# cyt6bj register map
Vendor: Cypress Semiconductor; Series: cyt6bj; File version: 1.0
CPU: CM7 r0p1, little endian, MPU, FPU, VTOR, 3 interrupt priority bits
Registers are 32-bit, read-write, reset 0x0 unless marked. A register's access mark holds for its fields unless they carry their own. Offsets are from the block's base; [hi:lo] are bit positions; lines under a group give offsets from that group; {n}, {i} and the like mark numbered series; <NAME> marks a mode.

## CANFD0 (part 2 of 3) — CAN Controller
Base 0x40520000
Same registers: CANFD1 0x40540000
{0x0+0x200*i} CH[{i}] (i=0..4) group — FIFO wrapper around M_TTCAN 3PIP, to enable DMA
  0x00 M_TTCAN group — TTCAN 3PIP, includes FD
    0xAC RXBC — Rx Buffer Configuration
      [15:2] RBSA — Rx Buffer Start Address Configures the start address of the Rx Buffers section in the Message RAM (32-bit word address). Also used to reference debug messages A,B,C.
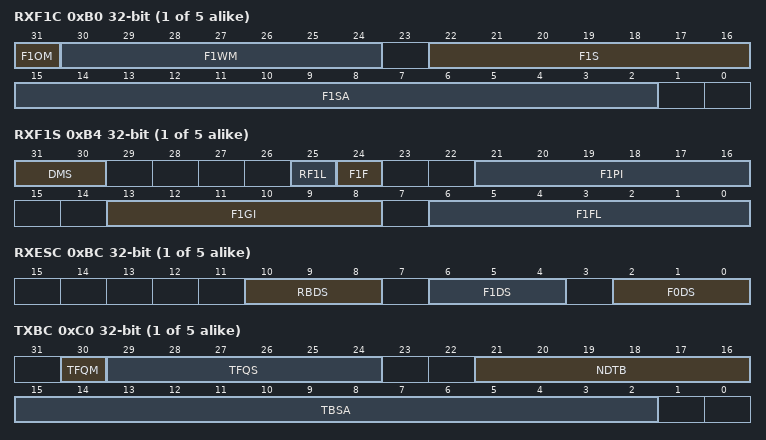
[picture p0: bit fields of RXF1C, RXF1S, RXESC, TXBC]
    0xB0 RXF1C — Rx FIFO 1 Configuration
      [31] F1OM — FIFO 1 Operation Mode FIFO 1 can be operated in blocking or in overwrite mode (see Section 3.4.2). 0= FIFO 1 blocking mode 1= FIFO 1 overwrite mode
      [30:24] F1WM — Rx FIFO 1 Watermark 0= Watermark interrupt disabled 1-64= Level for Rx FIFO 1 watermark interrupt (IR.RF1W) 64= Watermark interrupt disabled
      [22:16] F1S — Rx FIFO 1 Size 0= No Rx FIFO 1 1-64= Number of Rx FIFO 1 elements 64= Values greater than 64 are interpreted as 64 The Rx FIFO 1 elements are indexed from 0 to F1S - 1
      [15:2] F1SA — Rx FIFO 1 Start Address Start address of Rx FIFO 1 in Message RAM (32-bit word address, see Figure 2).
    0xB4 RXF1S ro — Rx FIFO 1 Status
      [31:30] DMS — Debug Message Status 00= Idle state, wait for reception of debug messages, DMA request is cleared 01= Debug message A received 10= Debug messages A, B received 11= Debug messages A, B, C received, DMA request is set
      [25] RF1L — Rx FIFO 1 Message Lost This bit is a copy of interrupt flag IR.RF1L. When IR.RF1L is reset, this bit is also reset. 0= No Rx FIFO 1 message lost 1= Rx FIFO 1 message lost, also set after write attempt to Rx FIFO 1 of size zero
      [24] F1F — Rx FIFO 1 Full 0= Rx FIFO 1 not full 1= Rx FIFO 1 full
      [21:16] F1PI — Rx FIFO 1 Put Index Rx FIFO 1 write index pointer, range 0 to 63.
      [13:8] F1GI — Rx FIFO 1 Get Index Rx FIFO 1 read index pointer, range 0 to 63. This field is updated by the software writing to RXF1A.F1AI. When the software reading the value immediately after writing to RXF1A.F1AI, this value should be read twice to ensure that the update is reflected.
      [6:0] F1FL — Rx FIFO 1 Fill Level Number of elements stored in Rx FIFO 1, range 0 to 64. When the software reading the value immediately after writing to RXF1A.F1AI, this value should be read twice to ensure that the update is reflected.
    0xB8 RXF1A — Rx FIFO 1 Acknowledge
      [5:0] F1AI — Rx FIFO 1 Acknowledge Index After the Host has read a message or a sequence of messages from Rx FIFO 1 it has to write the buffer index of the last element read from Rx FIFO 1 to F1AI. This will set the Rx FIFO 1 Get Index RXF1S.F1GI to F1AI + 1 and update the FIFO 1 Fill Level RXF1S.F1FL.
    0xBC RXESC — Rx Buffer / FIFO Element Size Configuration
      [10:8] RBDS — Rx Buffer Data Field Size 000= 8 byte data field 001= 12 byte data field 010= 16 byte data field 011= 20 byte data field 100= 24 byte data field 101= 32 byte data field 110= 48 byte data field 111= 64 byte data field
      [6:4] F1DS — Rx FIFO 1 Data Field Size 000= 8 byte data field 001= 12 byte data field 010= 16 byte data field 011= 20 byte data field 100= 24 byte data field 101= 32 byte data field 110= 48 byte data field 111= 64 byte data field
      [2:0] F0DS — Rx FIFO 0 Data Field Size 000= 8 byte data field 001= 12 byte data field 010= 16 byte data field 011= 20 byte data field 100= 24 byte data field 101= 32 byte data field 110= 48 byte data field 111= 64 byte data field
    0xC0 TXBC — Tx Buffer Configuration
      [30] TFQM — Tx FIFO/Queue Mode 0= Tx FIFO operation 1= Tx Queue operation
      [29:24] TFQS — Transmit FIFO/Queue Size 0= No Tx FIFO/Queue 1-32= Number of Tx Buffers used for Tx FIFO/Queue 32= Values greater than 32 are interpreted as 32
      [21:16] NDTB — Number of Dedicated Transmit Buffers 0= No Dedicated Tx Buffers 1-32= Number of Dedicated Tx Buffers 32= Values greater than 32 are interpreted as 32
      [15:2] TBSA — Tx Buffers Start Address Start address of Tx Buffers section in Message RAM (32-bit word address, see Figure 2).
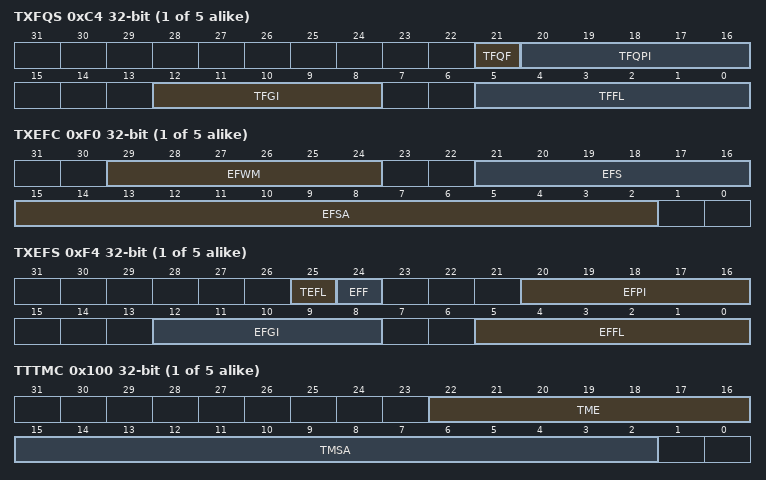
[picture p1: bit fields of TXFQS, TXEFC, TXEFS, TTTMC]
    0xC4 TXFQS ro — Tx FIFO/Queue Status
      [21] TFQF — Tx FIFO/Queue Full 0= Tx FIFO/Queue not full 1= Tx FIFO/Queue full
      [20:16] TFQPI — Tx FIFO/Queue Put Index Tx FIFO/Queue write index pointer, range 0 to 31.
      [12:8] TFGI — Tx FIFO Get Index Tx FIFO read index pointer, range 0 to 31. Read as zero when Tx Queue operation is configured TXBC.TFQM = '1').
      [5:0] TFFL — Tx FIFO Free Level Number of consecutive free Tx FIFO elements starting from TFGI, range 0 to 32. Read as zero when Tx Queue operation is configured (TXBC.TFQM = '1')
    0xC8 TXESC — Tx Buffer Element Size Configuration
      [2:0] TBDS — Tx Buffer Data Field Size 000= 8 byte data field 001= 12 byte data field 010= 16 byte data field 011= 20 byte data field 100= 24 byte data field 101= 32 byte data field 110= 48 byte data field 111= 64 byte data field
    0xCC TXBRP ro — Tx Buffer Request Pending
      [31:0] TRP — Transmission Request Pending Each Tx Buffer has its own Transmission Request Pending bit. The bits are set via register TXBAR. The bits are reset after a requested transmission has completed or has been cancelled via register TXBCR. TXBRP bits are set only for those Tx Buffers configured via TXBC. After a TXBRP bit has been set, a Tx scan (see Section 3.5, Tx Handling) is started to check for the pending Tx request with the highest priority (Tx Buffer with lowest Message ID). A cancellation request resets the corresponding transmission request pending bit of register TXBRP. In case a transmission has already been started when a cancellation is requested, this is done at the end of the transmission, regardless whether the transmission was successful or not. The cancellation request bits are reset directly after the corresponding TXBRP bit has been reset. After a cancellation has been requested, a finished cancellation is signaled via TXBCF after successful transmission together with the corresponding TXBTO bit when the transmission has not yet been started at the point of cancellation when the transmission has been aborted due to lost arbitration when an error occurred during frame transmission In DAR mode all transmissions are automatically cancelled if they are not successful. The corresponding TXBCF bit is set for all unsuccessful transmissions. 0= No transmission request pending 1= Transmission request pending
    0xD0 TXBAR — Tx Buffer Add Request
      [31:0] AR — Add Request Each Tx Buffer has its own Add Request bit. Writing a '1' will set the corresponding Add Request bit; writing a '0' has no impact. This enables the Host to set transmission requests for multiple Tx Buffers with one write to TXBAR. TXBAR bits are set only for those Tx Buffers configured via TXBC. When no Tx scan is running, the bits are reset immediately, else the bits remain set until the Tx scan process has completed. 0= No transmission request added 1= Transmission requested added
    0xD4 TXBCR — Tx Buffer Cancellation Request
      [31:0] CR — Cancellation Request Each Tx Buffer has its own Cancellation Request bit. Writing a '1' will set the corresponding Cancellation Request bit; writing a '0' has no impact. This enables the Host to set cancellation requests for multiple Tx Buffers with one write to TXBCR. TXBCR bits are set only for those Tx Buffers configured via TXBC. The bits remain set until the corresponding bit of TXBRP is reset. 0= No cancellation pending 1= Cancellation pending
    0xD8 TXBTO ro — Tx Buffer Transmission Occurred
      [31:0] TO — Transmission Occurred Each Tx Buffer has its own Transmission Occurred bit. The bits are set when the corresponding TXBRP bit is cleared after a successful transmission. The bits are reset when a new transmission is requested by writing a '1' to the corresponding bit of register TXBAR. 0= No transmission occurred 1= Transmission occurred
    0xDC TXBCF ro — Tx Buffer Cancellation Finished
      [31:0] CF — Cancellation Finished Each Tx Buffer has its own Cancellation Finished bit. The bits are set when the corresponding TXBRP bit is cleared after a cancellation was requested via TXBCR. In case the corresponding TXBRP bit was not set at the point of cancellation, CF is set immediately. The bits are reset when a new transmission is requested by writing a '1' to the corresponding bit of register TXBAR. 0= No transmit buffer cancellation 1= Transmit buffer cancellation finished
    0xE0 TXBTIE — Tx Buffer Transmission Interrupt Enable
      [31:0] TIE — Transmission Interrupt Enable Each Tx Buffer has its own Transmission Interrupt Enable bit. 0= Transmission interrupt disabled 1= Transmission interrupt enable
    0xE4 TXBCIE — Tx Buffer Cancellation Finished Interrupt Enable
      [31:0] CFIE — Cancellation Finished Interrupt Enable Each Tx Buffer has its own Cancellation Finished Interrupt Enable bit. 0= Cancellation finished interrupt disabled 1= Cancellation finished interrupt enabled
    0xF0 TXEFC — Tx Event FIFO Configuration
      [29:24] EFWM — Event FIFO Watermark 0= Watermark interrupt disabled 1-32= Level for Tx Event FIFO watermark interrupt (IR.TEFW) 32= Watermark interrupt disabled
      [21:16] EFS — Event FIFO Size 0= Tx Event FIFO disabled 1-32= Number of Tx Event FIFO elements 32= Values greater than 32 are interpreted as 32 The Tx Event FIFO elements are indexed from 0 to EFS-1
      [15:2] EFSA — Event FIFO Start Address Start address of Tx Event FIFO in Message RAM (32-bit word address, see Figure 2).
    0xF4 TXEFS ro — Tx Event FIFO Status
      [25] TEFL — Tx Event FIFO Element Lost This bit is a copy of interrupt flag IR.TEFL. When IR.TEFL is reset, this bit is also reset. 0= No Tx Event FIFO element lost 1= Tx Event FIFO element lost, also set after write attempt to Tx Event FIFO of size zero.
      [24] EFF — Event FIFO Full 0= Tx Event FIFO not full 1= Tx Event FIFO full
      [20:16] EFPI — Event FIFO Put Index Tx Event FIFO write index pointer, range 0 to 31.
      [12:8] EFGI — Event FIFO Get Index Tx Event FIFO read index pointer, range 0 to 31. This field is updated by the software writing to TXEFA.EFAI. When the software reading the value immediately after writing to TXEFA.EFAI, this value should be read twice to ensure that the update is reflected.
      [5:0] EFFL — Event FIFO Fill Level Number of elements stored in Tx Event FIFO, range 0 to 32. When the software reading the value immediately after writing to TXEFA.EFAI, this value should be read twice to ensure that the update is reflected.
    0xF8 TXEFA — Tx Event FIFO Acknowledge
      [4:0] EFAI — Event FIFO Acknowledge Index After the Host has read an element or a sequence of elements from the Tx Event FIFO it has to write the index of the last element read from Tx Event FIFO to EFAI. This will set the Tx Event FIFO Get Index TXEFS.EFGI to EFAI + 1 and update the Event FIFO Fill Level TXEFS.EFFL.
    0x100 TTTMC — TT Trigger Memory Configuration
      [22:16] TME — Trigger Memory Elements 0= No Trigger Memory 1-64= Number of Trigger Memory elements 64= Values greater than 64 are interpreted as 64
      [15:2] TMSA — Trigger Memory Start Address Start address of Trigger Memory in Message RAM (32-bit word address, see Figure 2).
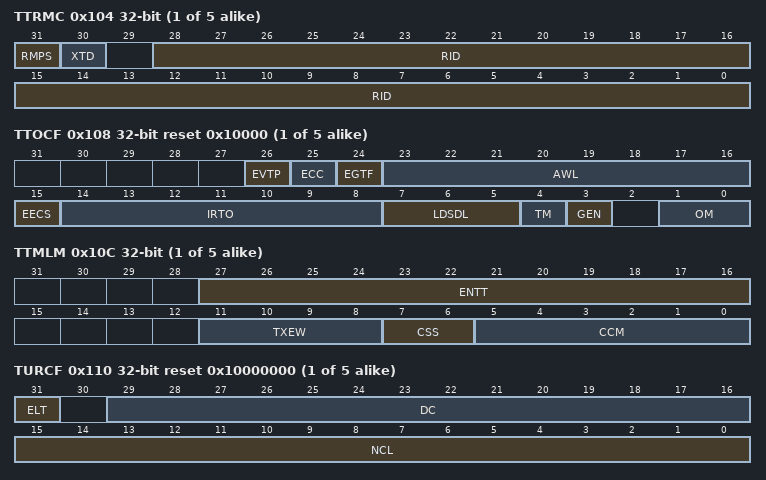
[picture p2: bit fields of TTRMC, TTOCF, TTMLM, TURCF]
    0x104 TTRMC — TT Reference Message Configuration
      [31] RMPS — Reference Message Payload Select Ignored in case of time slaves. 0= Reference message has no additional payload 1= The following elements are taken from Tx Buffer 0: Message Marker MM, Event FIFO Control EFC, Data Length Code DLC, Data Bytes DB Level 1: bytes 2-8, Level 0,2: bytes 5-8)
      [30] XTD — Extended Identifier 0= 11-bit standard identifier 1= 29-bit extended identifier
      [28:0] RID — Reference Identifier Identifier transmitted with reference message and used for reference message filtering. Standard or extended reference identifier depending on bit XTD. A standard identifier has to be written to ID[28:18].
    0x108 TTOCF reset 0x10000 — TT Operation Configuration
      [26] EVTP — Event Trigger Polarity 0= Rising edge trigger 1= Falling edge trigger
      [25] ECC — Enable Clock Calibration 0= Automatic clock calibration in TTCAN Level 0,2 is disabled 1= Automatic clock calibration in TTCAN Level 0,2 is enabled
      [24] EGTF — Enable Global Time Filtering 0= Global time filtering in TTCAN Level 0,2 is disabled 1= Global time filtering in TTCAN Level 0,2 is enabled
      [23:16] AWL — Application Watchdog Limit The application watchdog can be disabled by programming AWL to 0x00. 0x00-FF Maximum time after which the application has to serve the application watchdog. The application watchdog is incremented once each 256 NTUs.
      [15] EECS — Enable External Clock Synchronization If enabled, TUR configuration (TURCF.NCL only) may be updated during TTCAN operation. 0= External clock synchronization in TTCAN Level 0,2 disabled 1= External clock synchronization in TTCAN Level 0,2 enabled
      [14:8] IRTO — Initial Reference Trigger Offset 0x00-7F Positive offset, range from 0 to 127
      [7:5] LDSDL — LD of Synchronization Deviation Limit The Synchronization Deviation Limit SDL is configured by its dual logarithm LDSDL with SDL = 2(LDSDL + 5). It should not exceed the clock tolerance given by the CAN bit timing configuration. 0x0-7 LD of Synchronization Deviation Limit (SDL <= 32...4096)
      [4] TM — Time Master 0= Time Master function disabled 1= Potential Time Master
      [3] GEN — Gap Enable 0= Strictly time-triggered operation 1= External event-synchronized time-triggered operation
      [1:0] OM — Operation Mode 00= Event-driven CAN communication, default 01= TTCAN level 1 10= TTCAN level 2 11= TTCAN level 0
    0x10C TTMLM — TT Matrix Limits
      [27:16] ENTT — Expected Number of Tx Triggers 0x000-FFF Expected number of Tx Triggers in one Matrix Cycle
      [11:8] TXEW — Tx Enable Window 0x0-F Length of Tx enable window, 1-16 NTU cycles
      [7:6] CSS
      [5:0] CCM
    0x110 TURCF reset 0x10000000 — TUR Configuration
      [31] ELT — Enable Local Time 0= Local time is stopped, default 1= Local time is enabled
      [29:16] DC — Denominator Configuration 0x0000 Illegal value 0x0001-3FFF Denominator Configuration
      [15:0] NCL — Numerator Configuration Low Write access to the TUR Numerator Configuration Low is only possible during configuration with TURCF.ELT = '0' or if TTOCF.EECS (external clock synchronization enabled) is set. When a new value for NCL is written outside TT Configuration Mode, the new value takes effect when TTOST.WECS is cleared to '0'. NCL is locked TTOST.WECS is '1'. 0x0000-FFFF Numerator Configuration Low
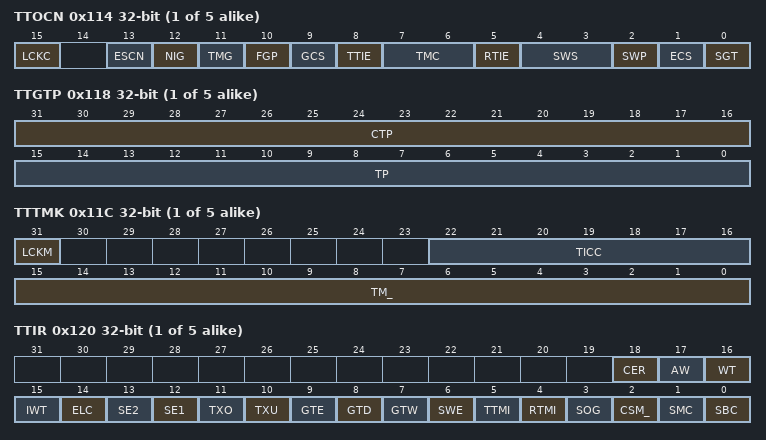
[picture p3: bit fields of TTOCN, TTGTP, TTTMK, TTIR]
    0x114 TTOCN — TT Operation Control
      [15] LCKC ro — TT Operation Control Register Locked Set by a write access to register TTOCN. Reset when the updated configuration has been synchronized into the CAN clock domain. 0= Write access to TTOCN enabled 1= Write access to TTOCN locked
      [13] ESCN — External Synchronization Control If enabled the M_TTCAN synchronizes its cycle time phase to an external event signaled by a rising edge at pin m_ttcan_evt (see Section 4.11). 0= External synchronization disabled 1= External synchronization enabled
      [12] NIG — Next is Gap This bit can only be set when the M_TTCAN is the actual Time Master and when it is configured for external event-synchronized time-triggered operation (TTOCF.GEN = '1') 0= No action, reset by reception of any reference message 1= Transmit next reference message with Next_is_Gap = '1'
      [11] TMG — Time Mark Gap 0= Reset by each reference message 1= Next reference message started when Register Time Mark interrupt TTIR.RTMI is activated
      [10] FGP — Finish Gap Set by the CPU, reset by each reference message 0= No reference message requested 1= Application requested start of reference message
      [9] GCS — Gap Control Select 0= Gap control independent from m_ttcan_evt 1= Gap control by input pin m_ttcan_evt
      [8] TTIE — Trigger Time Mark Interrupt Pulse Enable External time mark events are configured by trigger memory element TMEX (see Section 2.4.7). A trigger time mark interrupt pulse is generated when the trigger memory element becomes active, and the M_TTCAN is in synchronization state In_Schedule or In_Gap. 0= Trigger Time Mark Interrupt output m_ttcan_tmp disabled 1= Trigger Time Mark Interrupt output m_ttcan_tmp enabled
      [7:6] TMC — Register Time Mark Compare 00= No Register Time Mark Interrupt generated 01= Register Time Mark Interrupt if Time Mark = cycle time 10= Register Time Mark Interrupt if Time Mark = local time 11= Register Time Mark Interrupt if Time Mark = global time
      [5] RTIE — Register Time Mark Interrupt Pulse Enable Register time mark interrupts are configured by register TTTMK. A register time mark interrupt pulse with the length of one NTU is generated when the time referenced by TTOCN.TMC (cycle, local, or global) equals TTTMK.TM, independent of the synchronization state. 0= Register Time Mark Interrupt output m_ttcan_rtp disabled 1= Register Time Mark Interrupt output m_ttcan_rtp enabled
      [4:3] SWS — Stop Watch Source 00= Stop Watch disabled 01= Actual value of cycle time is copied to TTCPT.SWV 10= Actual value of local time is copied to TTCPT.SWV 11= Actual value of global time is copied to TTCPT.SWV
      [2] SWP — Stop Watch Polarity 0= Rising edge trigger 1= Falling edge trigger
      [1] ECS — External Clock Synchronization Writing a '1' to ECS sets TTOST.WECS if the node is the actual Time Master. ECS is reset after one Host clock period. The external clock synchronization takes effect at the start of the next basic cycle.
      [0] SGT — Set Global time Writing a '1' to SGT sets TTOST.WGDT if the node is the actual Time Master. SGT is reset after one Host clock period. The global time preset takes effect when the node transmits the next reference message with the Master_Ref_Mark modified by the preset value written to TTGTP.
    0x118 TTGTP — TT Global Time Preset
      [31:16] CTP — Cycle Time Target Phase CTP is write-protected while TTOCN.ESCN or TTOST.SPL are set (see Section 4.11). 0x0000-FFFF Defines target value of cycle time when a rising edge of m_ttcan_evt is expected
      [15:0] TP
    0x11C TTTMK — TT Time Mark
      [31] LCKM ro — TT Time Mark Register Locked Always set by a write access to registers TTOCN. Set by write access to register TTTMK when TTOCN.TMC != '00'. Reset when the registers have been synchronized into the CAN clock domain. 0= Write access to TTTMK enabled 1= Write access to TTTMK locked
      [22:16] TICC — Time Mark Cycle Code Cycle count for which the time mark is valid. 0b000000x valid for all cycles 0b000001c valid every second cycle at cycle count mod2 = c 0b00001cc valid every fourth cycle at cycle count mod4 = cc 0b0001ccc valid every eighth cycle at cycle count mod8 = ccc 0b001cccc valid every sixteenth cycle at cycle count mod16 = cccc 0b01ccccc valid every thirty-second cycle at cycle count mod32 = ccccc 0b1cccccc valid every sixty-fourth cycle at cycle count mod64 = cccccc
      [15:0] TM_ — Time Mark 0x0000-FFFF Time Mark
    0x120 TTIR — TT Interrupt Register
      [18] CER — Configuration Error Trigger out of order. 0= No error found in trigger list 1= Error found in trigger list
      [17] AW — Application Watchdog 0= Application watchdog served in time 1= Application watchdog not served in time
      [16] WT — Watch Trigger 0= No missing reference message 1= Missing reference message (Level 0: cycle time 0xFF00)
      [15] IWT — Initialization Watch Trigger The initialization is restarted by resetting IWT. 0= No missing reference message during system startup 1= No system startup due to missing reference message
      [14] ELC — Error Level Changed Not set when error level changed during initialization. 0= No change in error level 1= Error level changed
      [13] SE2 — Scheduling Error 2 0= No scheduling error 2 1= Scheduling error 2 occurred
      [12] SE1 — Scheduling Error 1 0= No scheduling error 1 1= Scheduling error 1 occurred
      [11] TXO — Tx Count Overflow 0= Number of Tx Trigger as expected 1= More Tx trigger than expected in one matrix cycle
      [10] TXU — Tx Count Underflow 0= Number of Tx Trigger as expected 1= Less Tx trigger than expected in one matrix cycle
      [9] GTE — Global Time Error Synchronization deviation SD exceeds limit specified by TTOCF.LDSDL, TTCAN Level 0,2 only. 0= Synchronization deviation within limit 1= Synchronization deviation exceeded limit
      [8] GTD — Global Time Discontinuity 0= No discontinuity of global time 1= Discontinuity of global time
      [7] GTW — Global Time Wrap 0= No global time wrap occurred 1= Global time wrap from 0xFFFF to 0x0000 occurred
      [6] SWE — Stop Watch Event 0= No rising/falling edge at stop watch trigger pin m_ttcan_swt detected 1= Rising/falling edge at stop watch trigger pin m_ttcan_swt detected
      [5] TTMI — Trigger Time Mark Event Internal Internal time mark events are configured by trigger memory element TMIN (see Section 2.4.7). Set when the trigger memory element becomes active, and the M_TTCAN is in synchronization state In_Gap or In_Schedule. 0= Time mark not reached 1= Time mark reached (Level 0: cycle time TTOCF.IRTO * 0x200)
      [4] RTMI — Register Time Mark Interrupt Set when time referenced by TTOCN.TMC (cycle, local, or global) equals TTTMK.TM, independent of the synchronization state. 0= Time mark not reached 1= Time mark reached
      [3] SOG — Start of Gap 0= No reference message seen with Next_is_Gap bit set 1= Reference message with Next_is_Gap bit set becomes valid
      [2] CSM_ — Change of Synchronization Mode 0= No change in master to slave relation or schedule synchronization 1= Master to slave relation or schedule synchronization changed, also set when TTOST.SPL is reset
      [1] SMC — Start of Matrix Cycle 0= No Matrix Cycle started since bit has been reset 1= Matrix Cycle started
      [0] SBC — Start of Basic Cycle 0= No Basic Cycle started since bit has been reset 1= Basic Cycle started
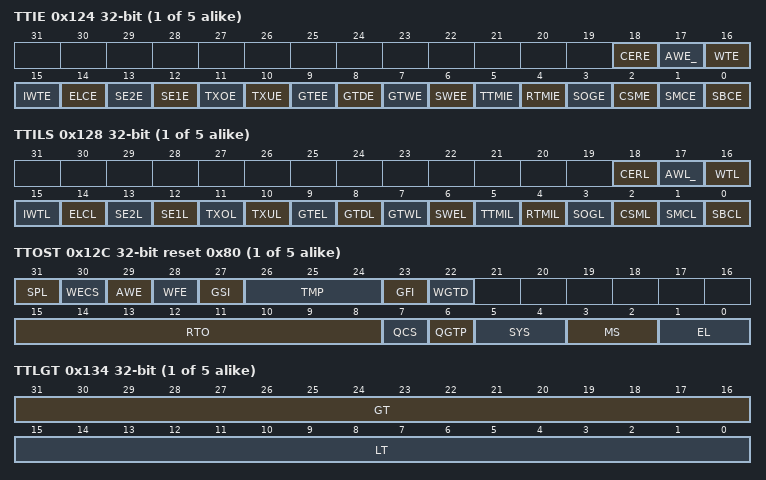
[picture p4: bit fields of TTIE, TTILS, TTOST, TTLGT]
    0x124 TTIE — TT Interrupt Enable
      [18] CERE — Configuration Error Interrupt Enable 0= Interrupt Disabled 1= Interrupt Enabled
      [17] AWE_ — Application Watchdog Interrupt Enable 0= Interrupt Disabled 1= Interrupt Enabled
      [16] WTE — Watch Trigger Interrupt Enable 0= Interrupt Disabled 1= Interrupt Enabled
      [15] IWTE — Initialization Watch Trigger Interrupt Enable 0= Interrupt Disabled 1= Interrupt Enabled
      [14] ELCE — Change Error Level Interrupt Enable 0= Interrupt Disabled 1= Interrupt Enabled
      [13] SE2E — Scheduling Error 2 Interrupt Enable 0= Interrupt Disabled 1= Interrupt Enabled
      [12] SE1E — Scheduling Error 1 Interrupt Enable 0= Interrupt Disabled 1= Interrupt Enabled
      [11] TXOE — Tx Count Overflow Interrupt Enable 0= Interrupt Disabled 1= Interrupt Enabled
      [10] TXUE — Tx Count Underflow Interrupt Enable 0= Interrupt Disabled 1= Interrupt Enabled
      [9] GTEE — Global Time Error Interrupt Enable 0= Interrupt Disabled 1= Interrupt Enabled
      [8] GTDE — Global Time Discontinuity Interrupt Enable 0= Interrupt Disabled 1= Interrupt Enabled
      [7] GTWE — Global Time Wrap Interrupt Enable 0= Interrupt Disabled 1= Interrupt Enabled
      [6] SWEE — Stop Watch Event Interrupt Enable 0= Interrupt Disabled 1= Interrupt Enabled
      [5] TTMIE — Trigger Time Mark Event Internal Enable 0= Interrupt Disabled 1= Interrupt Enabled
      [4] RTMIE — Register Time Mark Interrupt Enable 0= Interrupt Disabled 1= Interrupt Enabled
      [3] SOGE — Start of Gap Interrupt Enable 0= Interrupt Disabled 1= Interrupt Enabled
      [2] CSME — Change of Synchronization Mode Interrupt Enable 0= Interrupt Disabled 1= Interrupt Enabled
      [1] SMCE — Start of Matrix Cycle Interrupt Enable 0= Interrupt Disabled 1= Interrupt Enabled
      [0] SBCE — Start of Basic Cycle Interrupt Enable 0= Interrupt Disabled 1= Interrupt Enabled
    0x128 TTILS — TT Interrupt Line Select
      [18] CERL — Configuration Error Interrupt Select 0= Assign to interrupt enabled by ILE.EINT0 1= Assign to interrupt enabled by ILE.EINT1
      [17] AWL_ — Application Watchdog Interrupt Select 0= Assign to interrupt enabled by ILE.EINT0 1= Assign to interrupt enabled by ILE.EINT1
      [16] WTL — Watch Trigger Interrupt Select 0= Assign to interrupt enabled by ILE.EINT0 1= Assign to interrupt enabled by ILE.EINT1
      [15] IWTL — Initialization Watch Trigger Interrupt Select 0= Assign to interrupt enabled by ILE.EINT0 1= Assign to interrupt enabled by ILE.EINT1
      [14] ELCL — Change Error Level Interrupt Select 0= Assign to interrupt enabled by ILE.EINT0 1= Assign to interrupt enabled by ILE.EINT1
      [13] SE2L — Scheduling Error 2 Interrupt Select 0= Assign to interrupt enabled by ILE.EINT0 1= Assign to interrupt enabled by ILE.EINT1
      [12] SE1L — Scheduling Error 1 Interrupt Select 0= Assign to interrupt enabled by ILE.EINT0 1= Assign to interrupt enabled by ILE.EINT1
      [11] TXOL — Tx Count Overflow Interrupt Select 0= Assign to interrupt enabled by ILE.EINT0 1= Assign to interrupt enabled by ILE.EINT1
      [10] TXUL — Tx Count Underflow Interrupt Select 0= Assign to interrupt enabled by ILE.EINT0 1= Assign to interrupt enabled by ILE.EINT1
      [9] GTEL — Global Time Error Interrupt Select 0= Assign to interrupt enabled by ILE.EINT0 1= Assign to interrupt enabled by ILE.EINT1
      [8] GTDL — Global Time Discontinuity Interrupt Select 0= Assign to interrupt enabled by ILE.EINT0 1= Assign to interrupt enabled by ILE.EINT1
      [7] GTWL — Global Time Wrap Interrupt Select 0= Assign to interrupt enabled by ILE.EINT0 1= Assign to interrupt enabled by ILE.EINT1
      [6] SWEL — Stop Watch Event Interrupt Select 0= Assign to interrupt enabled by ILE.EINT0 1= Assign to interrupt enabled by ILE.EINT1
      [5] TTMIL — Trigger Time Mark Event Internal Select 0= Assign to interrupt enabled by ILE.EINT0 1= Assign to interrupt enabled by ILE.EINT1
      [4] RTMIL — Register Time Mark Interrupt Select 0= Assign to interrupt enabled by ILE.EINT0 1= Assign to interrupt enabled by ILE.EINT1
      [3] SOGL — Start of Gap Interrupt Select 0= Assign to interrupt enabled by ILE.EINT0 1= Assign to interrupt enabled by ILE.EINT1
      [2] CSML — Change of Synchronization Mode Interrupt Select 0= Assign to interrupt enabled by ILE.EINT0 1= Assign to interrupt enabled by ILE.EINT1
      [1] SMCL — Start of Matrix Cycle Interrupt Select 0= Assign to interrupt enabled by ILE.EINT0 1= Assign to interrupt enabled by ILE.EINT1
      [0] SBCL — Start of Basic Cycle Interrupt Select 0= Assign to interrupt enabled by ILE.EINT0 1= Assign to interrupt enabled by ILE.EINT1
    0x12C TTOST ro reset 0x80 — TT Operation Status
      [31] SPL — Schedule Phase Lock The bit is valid only when external synchronization is enabled (TTOCN.ESCN = '1'). In this case it signals that the difference between cycle time configured by TTGTP.CTP and the cycle time at the rising edge at pin m_ttcan_evt is less or equal 9 NTU (see Section 4.11). 0= Phase outside range 1= Phase inside range
      [30] WECS — Wait for External Clock Synchronization 0= No external clock synchronization pending 1= Node waits for external clock synchronization to take effect. The bit is reset at the start of the next basic cycle.
      [29] AWE — Application Watchdog Event The application watchdog is served by reading TTOST. When the watchdog is not served in time, bit AWE is set, all TTCAN communication is stopped, and the M_TTCAN is set into Bus Monitoring Mode. 0= Application Watchdog served in time 1= Failed to serve Application Watchdog in time
      [28] WFE — Wait for Event 0= No Gap announced, reset by a reference message with Next_is_Gap = '0' 1= Reference message with Next_is_Gap = '1' received
      [27] GSI — Gap Started Indicator 0= No Gap in schedule, reset by each reference message and for all time slaves 1= Gap time after Basic Cycle has started
      [26:24] TMP — Time Master Priority 0x0-7 Priority of actual Time Master
      [23] GFI — Gap Finished Indicator Set when the CPU writes TTOCN.FGP, or by a time mark interrupt if TMG = '1', or via input pin m_ttcan_evt if TTOCN.GCS = '1'. Not set by Ref_Trigger_Gap or when Gap is finished by another node sending a reference message. 0= Reset at the end of each reference message 1= Gap finished by M_TTCAN
      [22] WGTD — Wait for Global Time Discontinuity 0= No global time preset pending 1= Node waits for the global time preset to take effect. The bit is reset when the node has transmitted a reference message with Disc_Bit = '1' or after it received a reference message.
      [15:8] RTO — Reference Trigger Offset The Reference Trigger Offset value is a signed integer with a range from -127 (0x81) to 127 (0x7F). There is no notification when the lower limit of -127 is reached. In case the M_TTCAN becomes Time Master (MS[1:0] = '11'), the reset of RTO is delayed due to synchronization between Host and CAN clock domain. For time slaves the value configured by TTOCF.IRTO is read. 0x00-FF Actual Reference Trigger offset value
      [7] QCS — Quality of Clock Speed Only relevant in TTCAN Level 0 and Level 2, otherwise fixed to '1'. 0= Local clock speed not synchronized to Time Master clock speed 1= Synchronization Deviation <= SDL
      [6] QGTP — Quality of Global Time Phase Only relevant in TTCAN Level 0 and Level 2, otherwise fixed to '0'. 0= Global time not valid 1= Global time in phase with Time Master
      [5:4] SYS — Synchronization State 00= Out of Synchronization 01= Synchronizing to TTCAN communication 10= Schedule suspended by Gap (In_Gap) 11= Synchronized to schedule (In_Schedule)
      [3:2] MS — Master State 00= Master_Off, no master properties relevant 01= Operating as Time Slave 10= Operating as Backup Time Master 11= Operating as current Time Master
      [1:0] EL — Error Level 00= Severity 0 - No Error 01= Severity 1 - Warning 10= Severity 2 - Error 11= Severity 3 - Severe Error
    0x130 TURNA ro reset 0x10000 — TUR Numerator Actual
      [17:0] NAV
    0x134 TTLGT ro — TT Local & Global Time
      [31:16] GT — Global Time Non-fractional part of the sum of the node's local time and its local offset (see Section 4.5). 0x0000-FFFF Global time value of TTCAN network
      [15:0] LT — Local Time Non-fractional part of local time, incremented once each local NTU (see Section 4.5). 0x0000-FFFF Local time value of TTCAN node
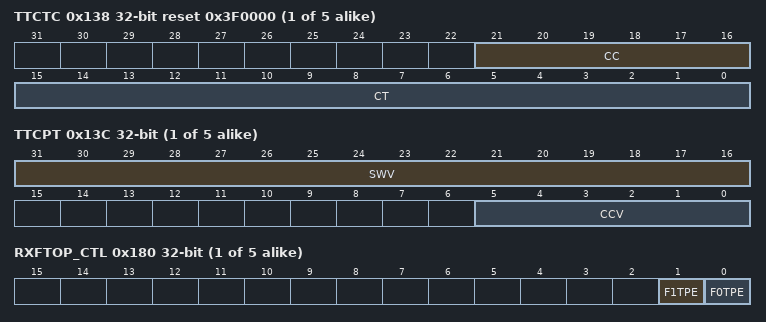
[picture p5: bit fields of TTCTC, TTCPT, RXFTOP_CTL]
    0x138 TTCTC ro reset 0x3F0000 — TT Cycle Time & Count
      [21:16] CC — Cycle Count 0x00-3F Number of actual Basic Cycle in the System Matrix
      [15:0] CT — Cycle Time Non-fractional part of the difference of the node's local time and Ref_Mark (see Section 4.5). 0x0000-FFFF Cycle time value of TTCAN Basic Cycle
    0x13C TTCPT ro — TT Capture Time
      [31:16] SWV — Stop Watch Value On a rising/falling edge (as configured via TTOCN.SWP) at the Stop Watch Trigger pin m_ttcan_swt, when TTOCN.SWS is != '00' and TTIR.SWE is '0', the actual time value as selected by TTOCN.SWS (cycle, local, global) is copied to SWV and TTIR.SWE will be set to '1'. Capturing of the next stop watch value is enabled by resetting TTIR.SWE. 0x0000-FFFF Captured Stop Watch value
      [5:0] CCV — Cycle Count Value Cycle count value captured together with SWV. 0x00-3F Captured cycle count value
    0x140 TTCSM ro — TT Cycle Sync Mark
      [15:0] CSM — Cycle Sync Mark The Cycle Sync Mark is measured
  0x180 RXFTOP_CTL — Receive FIFO Top control
    [1] F1TPE — FIFO 1 Top Pointer Enable.
    [0] F0TPE — FIFO 0 Top Pointer Enable. This enables the FIFO top pointer logic to set the FIFO Top Address (FnTA) and message word counter. This logic is also disabled when the IP is being reconfigured (CCCR.CCE=1). When this logic is disabled a Read from RXFTOP0_DATA is undefined.
  0x1A0 RXFTOP0_STAT ro — Receive FIFO 0 Top Status
    [15:0] F0TA — Current FIFO 0 Top Address. This is a pointer to the next word in the message buffer defined by the FIFO Start Address (FnSA), Get Index (FnGI), the FIFO message size (FnDS) and the message word counter (FnMWC) FnTA = FnSA + FnGI * msg_size[FnDS] + FnMWC
  0x1A8 RXFTOP0_DATA ro reset not defined — Receive FIFO 0 Top Data
    [31:0] F0TD — When enabled (F0TPE=1) read data from MRAM at location FnTA. This register can have a read side effect if the following conditions are met: - M_TTCAN not being reconfigured (CCCR.CCE=0) - FIFO Top Pointer logic is enabled (FnTPE=1) - FIFO is not empty (FnFL!=0) The read side effect is as follows: - if FnMWC pointed to the last word of the message (as indicated by FnDS) then the corresponding message index (FnGI) is automatically acknowledge by a write to FnAI - FnMWC is incremented (or restarted if FnMWC pointed to the last word of the message) - the FIFO top address FnTA is incremented (with FIFO wrap around) When this logic is disabled (F0TPE=0) a Read from this register returns undefined data.
  0x1B0 RXFTOP1_STAT ro — Receive FIFO 1 Top Status
    [15:0] F1TA — See F0TA description
  0x1B8 RXFTOP1_DATA ro reset not defined — Receive FIFO 1 Top Data
    [31:0] F1TD — See F0TD description
